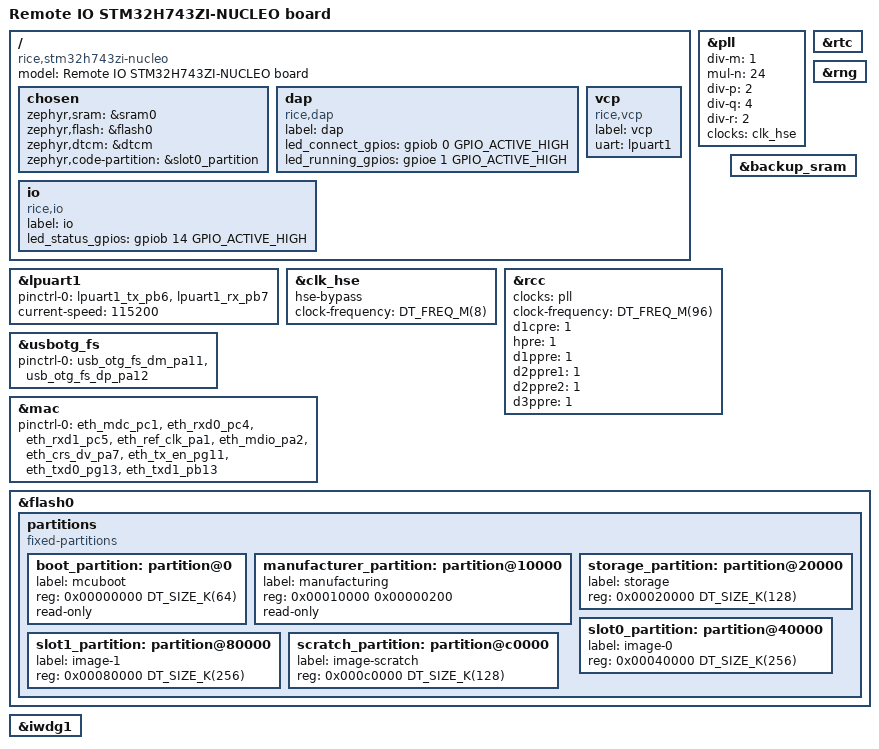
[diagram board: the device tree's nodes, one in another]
/dts-v1/;
#include <st/h7/stm32h743Xi.dtsi>
#include <st/h7/stm32h743zitx-pinctrl.dtsi>

/ {
    model = "Remote IO STM32H743ZI-NUCLEO board";
    compatible = "rice,stm32h743zi-nucleo";

    chosen {
        zephyr,sram = &sram0;
        zephyr,flash = &flash0;
        zephyr,dtcm = &dtcm;
        zephyr,code-partition = &slot0_partition;
    };

    dap: dap {
        label = "dap";
        compatible = "rice,dap";
        led_connect_gpios = <&gpiob 0 GPIO_ACTIVE_HIGH>;
        led_running_gpios = <&gpioe 1 GPIO_ACTIVE_HIGH>;
    };

    io: io {
        label = "io";
        compatible = "rice,io";
        led_status_gpios = <&gpiob 14 GPIO_ACTIVE_HIGH>;
    };

    vcp: vcp {
        label = "vcp";
        compatible = "rice,vcp";
        uart = <&lpuart1>;
    };
};

&lpuart1 {
    pinctrl-0 = <&lpuart1_tx_pb6 &lpuart1_rx_pb7>;
	pinctrl-names = "default";
	current-speed = <115200>;
    status = "okay";
};

// STLink 8MHz clock
&clk_hse {
    hse-bypass;
    clock-frequency = <DT_FREQ_M(8)>;
    status = "okay";
};

&pll {
    div-m = <1>;
    mul-n = <24>;
    div-p = <2>;
    div-q = <4>;
    div-r = <2>;
    clocks = <&clk_hse>;
    status = "okay";
};

&rcc {
    clocks = <&pll>;
    clock-frequency = <DT_FREQ_M(96)>;
    d1cpre = <1>;
    hpre = <1>;
    d1ppre = <1>;
    d2ppre1 = <1>;
    d2ppre2 = <1>;
    d3ppre = <1>;
};

usbd: &usbotg_fs {
    pinctrl-0 = <&usb_otg_fs_dm_pa11 &usb_otg_fs_dp_pa12>;
    pinctrl-names = "default";
    status = "okay";
};

&rtc {
    status = "okay";
};

&rng {
    status = "okay";
};

/*
 * WARNING:
 * Possible pin conflicts:
 *          The pins PA2 and PB13 may conflict on selection of ETH_STM32_HAL,
 *          since they are used in ST Zio or ST morpho connectors.
 *          To avoid conflicting states the jumpers JP6 and JP7
 *          must be in ON state.
 */
&mac {
    status = "okay";
    pinctrl-0 = <&eth_mdc_pc1
             &eth_rxd0_pc4
             &eth_rxd1_pc5
             &eth_ref_clk_pa1
             &eth_mdio_pa2
             &eth_crs_dv_pa7
             &eth_tx_en_pg11
             &eth_txd0_pg13
             &eth_txd1_pb13>;
    pinctrl-names = "default";
};
 
&backup_sram {
    status = "okay";
};

&flash0 {
    partitions {
        compatible = "fixed-partitions";
        #address-cells = <1>;
        #size-cells = <1>;

        /* 64KB for bootloader */
        boot_partition: partition@0 {
            label = "mcuboot";
            reg = <0x00000000 DT_SIZE_K(64)>;
            read-only;
        };

        /* 512B for manufacturing data */
        manufacturer_partition: partition@10000 {
			label = "manufacturing";
			reg = <0x00010000 0x00000200>;
			read-only;
		};

        /* storage: 128KB for settings */
        storage_partition: partition@20000 {
            label = "storage";
            reg = <0x00020000 DT_SIZE_K(128)>;
        };

        /* application image slot: 256KB */
        slot0_partition: partition@40000 {
            label = "image-0";
            reg = <0x00040000 DT_SIZE_K(256)>;
        };

        /* backup slot: 256KB */
        slot1_partition: partition@80000 {
            label = "image-1";
            reg = <0x00080000 DT_SIZE_K(256)>;
        };

        /* swap slot: 128KB */
        scratch_partition: partition@c0000 {
            label = "image-scratch";
            reg = <0x000c0000 DT_SIZE_K(128)>;
        };
    };
};
 
&iwdg1 {
    status = "okay";
};
